# apollo510 register map
Vendor: Ambiq Micro; Series: Apollo; File version: 1.0
CPU: CM55 r1p1, little endian, MPU, FPU, double-precision FPU, DSP, I-cache, D-cache, VTOR, ITCM, DTCM, 4 interrupt priority bits, 0 interrupts, 8 SAU regions
Registers are 32-bit, read-write, reset 0x0 unless marked. A register's access mark holds for its fields unless they carry their own. Offsets are from the block's base; [hi:lo] are bit positions; {n}, {i} and the like mark numbered series; 'fields as' and 'values as' point back to an identical list.

## GPIO (part 5 of 7) — General Purpose IO
Base 0x40010000
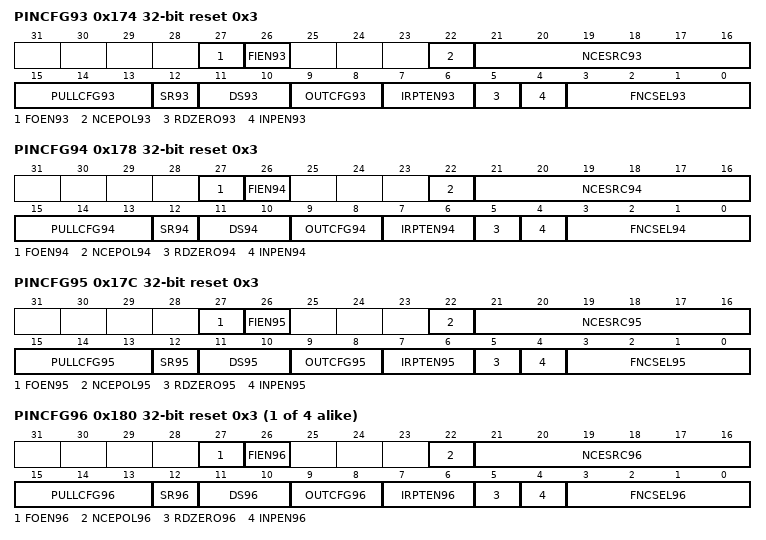
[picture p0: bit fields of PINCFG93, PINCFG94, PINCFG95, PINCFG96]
0x174 PINCFG93 reset 0x3 — Controls the operation of GPIO pin 93.
  [27] FOEN93 — Force output enable active regardless of function selected. Otherwise the selected function will enable the output only when needed
  [26] FIEN93 — Force input enable active regardless of function selected. Otherwise the selected function will enable the input only when needed
  [22] NCEPOL93 — Polarity select for NCE for GPIO 93
    0=LOW (Polarity is active low); 1=HIGH (Polarity is active high)
  [21:16] NCESRC93 — IOMSTR/MSPI N Chip Select 93, DISP control signals DE, CSX, and CS. Polarity is determined by CE_POLARITY field
    {v}=IOM0CE{v} (IOM 0 NCE {v} module) (v=0..3); {v}=IOM1CE{v-4} (IOM 1 NCE {v-4} module) (v=4..7); {v}=IOM2CE{v-8} (IOM 2 NCE {v-8} module) (v=8..11); {v}=IOM3CE{v-12} (IOM 3 NCE {v-12} module) (v=12..15); {v}=IOM4CE{v-16} (IOM 4 NCE {v-16} module) (v=16..19); {v}=IOM5CE{v-20} (IOM 5 NCE {v-20} module) (v=20..23); {v}=IOM6CE{v-24} (IOM 6 NCE {v-24} module) (v=24..27); {v}=IOM7CE{v-28} (IOM 7 NCE {v-28} module) (v=28..31); 48=DC_DPI_DE (DC DPI DE module); 49=DISP_CONT_CSX (DISP CONT CSX module); 50=DC_SPI_CS_N (DC SPI CS_N module); 51=DC_QSPI_CS_N (DC QSPI CS_N module); 52=DC_RESX (DC module RESX)
  [15:13] PULLCFG93 — Pullup/Pulldown configuration for GPIO 93
    0=DIS (No pullup or pulldown selected); 1=PD50K (50K Pulldown selected); 2=PU15K (1.5K Pullup selected); 3=PU6K (6K Pullup selected); 4=PU12K (12K Pullup selected); 5=PU24K (24K Pullup selected); 6=PU50K (50K Pullup selected); 7=PU100K (100K Pullup selected)
  [12] SR93 — Configure the slew rate
  [11:10] DS93 — Drive strength selection for GPIO 93
    0=0P1X (0.1x output driver selected); 1=0P5X (0.5x output driver selected)
  [9:8] OUTCFG93 — Pin IO mode selection for GPIO pin 93
    0=DIS (Output Disabled); 1=PUSHPULL (Output configured in push pull mode. Will drive 0 and 1 values on pin.); 2=OD (Output configured in open drain mode. Will only drive pin low, tristate otherwise.); 3=TS (Output configured in Tristate-able push pull mode. Will drive 0, 1 of HiZ on pin.)
  [7:6] IRPTEN93 — Interrupt enable for GPIO 93
    0=DIS (Interrupts are disabled for this GPIO); 1=INTFALL (Interrupts are enabled for falling edge transition on this GPIO); 2=INTRISE (Interrupts are enabled for rising edge transitions on this GPIO); 3=INTANY (Interrupts are enabled for any edge transition on this GPIO)
  [5] RDZERO93 — Return 0 for read data on GPIO 93
  [4] INPEN93 — Input enable for GPIO 93
  [3:0] FNCSEL93 — Function select for GPIO pin 93
    0=MNCE1_0 (MSPI Master 1 nCE 0 Signal); 3=GPIO (General purpose I/O); 6=CT93 (Timer/Counter input or output; Selection of direction is done via CTIMER register settings.); 7=NCE93 (IOMSTR N Chip Select. Polarity is determined by CE_POLARITY field); 8=OBSBUS13 (Observation bus bit 13); 9=VCMPO (Output of the voltage comparator signal); 11=FPIO (Fast PIO)
0x178 PINCFG94 reset 0x3 — Controls the operation of GPIO pin 94.
  [27] FOEN94 — Force output enable active regardless of function selected. Otherwise the selected function will enable the output only when needed
  [26] FIEN94 — Force input enable active regardless of function selected. Otherwise the selected function will enable the input only when needed
  [22] NCEPOL94 — Polarity select for NCE for GPIO 94
    values as PINCFG93.NCEPOL93
  [21:16] NCESRC94 — IOMSTR/MSPI N Chip Select 94, DISP control signals DE, CSX, and CS. Polarity is determined by CE_POLARITY field
    values as PINCFG93.NCESRC93
  [15:13] PULLCFG94 — Pullup/Pulldown configuration for GPIO 94
    values as PINCFG93.PULLCFG93
  [12] SR94 — Configure the slew rate
  [11:10] DS94 — Drive strength selection for GPIO 94
    values as PINCFG93.DS93
  [9:8] OUTCFG94 — Pin IO mode selection for GPIO pin 94
    values as PINCFG93.OUTCFG93
  [7:6] IRPTEN94 — Interrupt enable for GPIO 94
    values as PINCFG93.IRPTEN93
  [5] RDZERO94 — Return 0 for read data on GPIO 94
  [4] INPEN94 — Input enable for GPIO 94
  [3:0] FNCSEL94 — Function select for GPIO pin 94
    3=GPIO (General purpose I/O); 6=CT94 (Timer/Counter input or output; Selection of direction is done via CTIMER register settings.); 7=NCE94 (IOMSTR N Chip Select. Polarity is determined by CE_POLARITY field); 8=OBSBUS14 (Observation bus bit 14); 9=VCMPO (Output of the voltage comparator signal); 11=FPIO (Fast PIO)
0x17C PINCFG95 reset 0x3 — Controls the operation of GPIO pin 95.
  [27] FOEN95 — Force output enable active regardless of function selected. Otherwise the selected function will enable the output only when needed
  [26] FIEN95 — Force input enable active regardless of function selected. Otherwise the selected function will enable the input only when needed
  [22] NCEPOL95 — Polarity select for NCE for GPIO 95
    values as PINCFG93.NCEPOL93
  [21:16] NCESRC95 — IOMSTR/MSPI N Chip Select 95, DISP control signals DE, CSX, and CS. Polarity is determined by CE_POLARITY field
    values as PINCFG93.NCESRC93
  [15:13] PULLCFG95 — Pullup/Pulldown configuration for GPIO 95
    values as PINCFG93.PULLCFG93
  [12] SR95 — Configure the slew rate
  [11:10] DS95 — Drive strength selection for GPIO 95
    0=0P1X (0.1x output driver selected); 1=0P5X (0.5x output driver selected); 2=0P75X (0.75x output driver selected); 3=1P0X (1.0x output driver selected)
  [9:8] OUTCFG95 — Pin IO mode selection for GPIO pin 95
    values as PINCFG93.OUTCFG93
  [7:6] IRPTEN95 — Interrupt enable for GPIO 95
    values as PINCFG93.IRPTEN93
  [5] RDZERO95 — Return 0 for read data on GPIO 95
  [4] INPEN95 — Input enable for GPIO 95
  [3:0] FNCSEL95 — Function select for GPIO pin 95
    0=MSPI1_0 (MSPI Master 1 Interface Signal); 3=GPIO (General purpose I/O); 6=CT95 (Timer/Counter input or output; Selection of direction is done via CTIMER register settings.); 7=NCE95 (IOMSTR N Chip Select. Polarity is determined by CE_POLARITY field); 8=OBSBUS15 (Observation bus bit 15); 9=I2S0_SDIN (I2S Data input (I2S Master/Slave 0)); 11=FPIO (Fast PIO)
{0x0+4i} PINCFG{i} reset 0x3 (i=96..99) — Controls the operation of GPIO pin {i}.
  [27] FOEN{i} — Force output enable active regardless of function selected. Otherwise the selected function will enable the output only when needed
  [26] FIEN{i} — Force input enable active regardless of function selected. Otherwise the selected function will enable the input only when needed
  [22] NCEPOL{i} — Polarity select for NCE for GPIO {i}
    values as PINCFG93.NCEPOL93
  [21:16] NCESRC{i} — IOMSTR/MSPI N Chip Select {i}, DISP control signals DE, CSX, and CS. Polarity is determined by CE_POLARITY field
    values as PINCFG93.NCESRC93
  [15:13] PULLCFG{i} — Pullup/Pulldown configuration for GPIO {i}
    values as PINCFG93.PULLCFG93
  [12] SR{i} — Configure the slew rate
  [11:10] DS{i} — Drive strength selection for GPIO {i}
    values as PINCFG95.DS95
  [9:8] OUTCFG{i} — Pin IO mode selection for GPIO pin {i}
    values as PINCFG93.OUTCFG93
  [7:6] IRPTEN{i} — Interrupt enable for GPIO {i}
    values as PINCFG93.IRPTEN93
  [5] RDZERO{i} — Return 0 for read data on GPIO {i}
  [4] INPEN{i} — Input enable for GPIO {i}
  [3:0] FNCSEL{i} — Function select for GPIO pin {i}
    0=MSPI1_{i-95} (MSPI Master 1 Interface Signal); 3=GPIO (General purpose I/O); 6=CT{i} (Timer/Counter input or output; Selection of direction is done via CTIMER register settings.); 7=NCE{i} (IOMSTR N Chip Select. Polarity is determined by CE_POLARITY field); 8=OBSBUS{i-96} (Observation bus bit {i-96}); 11=FPIO (Fast PIO)
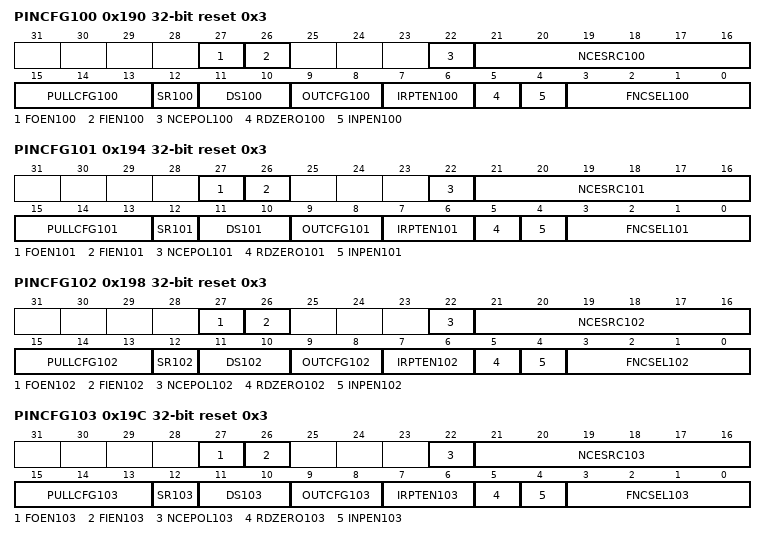
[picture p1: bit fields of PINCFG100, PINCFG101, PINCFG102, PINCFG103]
0x190 PINCFG100 reset 0x3 — Controls the operation of GPIO pin 100.
  [27] FOEN100 — Force output enable active regardless of function selected. Otherwise the selected function will enable the output only when needed
  [26] FIEN100 — Force input enable active regardless of function selected. Otherwise the selected function will enable the input only when needed
  [22] NCEPOL100 — Polarity select for NCE for GPIO 100
    values as PINCFG93.NCEPOL93
  [21:16] NCESRC100 — IOMSTR/MSPI N Chip Select 100, DISP control signals DE, CSX, and CS. Polarity is determined by CE_POLARITY field
    values as PINCFG93.NCESRC93
  [15:13] PULLCFG100 — Pullup/Pulldown configuration for GPIO 100
    values as PINCFG93.PULLCFG93
  [12] SR100 — Configure the slew rate
  [11:10] DS100 — Drive strength selection for GPIO 100
    values as PINCFG95.DS95
  [9:8] OUTCFG100 — Pin IO mode selection for GPIO pin 100
    values as PINCFG93.OUTCFG93
  [7:6] IRPTEN100 — Interrupt enable for GPIO 100
    values as PINCFG93.IRPTEN93
  [5] RDZERO100 — Return 0 for read data on GPIO 100
  [4] INPEN100 — Input enable for GPIO 100
  [3:0] FNCSEL100 — Function select for GPIO pin 100
    0=MSPI1_5 (MSPI Master 1 Interface Signal); 1=DISP_QSPI_D0_OUT (Display SPI Data0 Out); 2=DISP_QSPI_D0 (Display SPI Data0); 3=GPIO (General purpose I/O); 4=DISP_SPI_SD (Display SPI Data); 5=DISP_SPI_SDO (Display SPI Data Out); 6=CT100 (Timer/Counter input or output; Selection of direction is done via CTIMER register settings.); 7=NCE100 (IOMSTR N Chip Select. Polarity is determined by CE_POLARITY field); 8=OBSBUS4 (Observation bus bit 4); 9=I2S0_CLK (Bidirectional I2S Bit clock. Operates in output mode in master mode and input mode for slave mode. (I2S Master/Slave 0)); 11=FPIO (Fast PIO)
0x194 PINCFG101 reset 0x3 — Controls the operation of GPIO pin 101.
  [27] FOEN101 — Force output enable active regardless of function selected. Otherwise the selected function will enable the output only when needed
  [26] FIEN101 — Force input enable active regardless of function selected. Otherwise the selected function will enable the input only when needed
  [22] NCEPOL101 — Polarity select for NCE for GPIO 101
    values as PINCFG93.NCEPOL93
  [21:16] NCESRC101 — IOMSTR/MSPI N Chip Select 101, DISP control signals DE, CSX, and CS. Polarity is determined by CE_POLARITY field
    values as PINCFG93.NCESRC93
  [15:13] PULLCFG101 — Pullup/Pulldown configuration for GPIO 101
    values as PINCFG93.PULLCFG93
  [12] SR101 — Configure the slew rate
  [11:10] DS101 — Drive strength selection for GPIO 101
    values as PINCFG95.DS95
  [9:8] OUTCFG101 — Pin IO mode selection for GPIO pin 101
    values as PINCFG93.OUTCFG93
  [7:6] IRPTEN101 — Interrupt enable for GPIO 101
    values as PINCFG93.IRPTEN93
  [5] RDZERO101 — Return 0 for read data on GPIO 101
  [4] INPEN101 — Input enable for GPIO 101
  [3:0] FNCSEL101 — Function select for GPIO pin 101
    0=MSPI1_6 (MSPI Master 1 Interface Signal); 2=DISP_QSPI_D1 (Display SPI Data1); 3=GPIO (General purpose I/O); 4=DISP_SPI_DCX (Display SPI DCx); 6=CT101 (Timer/Counter input or output; Selection of direction is done via CTIMER register settings.); 7=NCE101 (IOMSTR N Chip Select. Polarity is determined by CE_POLARITY field); 8=OBSBUS5 (Observation bus bit 5); 9=I2S0_DATA (Bidirectional I2S Data. Operates in output mode in master mode and input mode for slave mode. (I2S Master/Slave 0)); 10=I2S0_SDOUT (I2S Data output (I2S Master/Slave 0)); 11=FPIO (Fast PIO)
0x198 PINCFG102 reset 0x3 — Controls the operation of GPIO pin 102.
  [27] FOEN102 — Force output enable active regardless of function selected. Otherwise the selected function will enable the output only when needed
  [26] FIEN102 — Force input enable active regardless of function selected. Otherwise the selected function will enable the input only when needed
  [22] NCEPOL102 — Polarity select for NCE for GPIO 102
    values as PINCFG93.NCEPOL93
  [21:16] NCESRC102 — IOMSTR/MSPI N Chip Select 102, DISP control signals DE, CSX, and CS. Polarity is determined by CE_POLARITY field
    values as PINCFG93.NCESRC93
  [15:13] PULLCFG102 — Pullup/Pulldown configuration for GPIO 102
    values as PINCFG93.PULLCFG93
  [12] SR102 — Configure the slew rate
  [11:10] DS102 — Drive strength selection for GPIO 102
    values as PINCFG95.DS95
  [9:8] OUTCFG102 — Pin IO mode selection for GPIO pin 102
    values as PINCFG93.OUTCFG93
  [7:6] IRPTEN102 — Interrupt enable for GPIO 102
    values as PINCFG93.IRPTEN93
  [5] RDZERO102 — Return 0 for read data on GPIO 102
  [4] INPEN102 — Input enable for GPIO 102
  [3:0] FNCSEL102 — Function select for GPIO pin 102
    0=MSPI1_7 (MSPI Master 1 Interface Signal); 2=DISP_QSPI_SCK (Display SPI CLK); 3=GPIO (General purpose I/O); 4=DISP_SPI_SCK (Display SPI Clock); 6=CT102 (Timer/Counter input or output; Selection of direction is done via CTIMER register settings.); 7=NCE102 (IOMSTR N Chip Select. Polarity is determined by CE_POLARITY field); 8=OBSBUS6 (Observation bus bit 6); 9=I2S0_WS (Bidirectional I2S L/R clock. Operates in output mode in master mode and input mode for slave mode. (I2S Master/Slave 0)); 11=FPIO (Fast PIO)
0x19C PINCFG103 reset 0x3 — Controls the operation of GPIO pin 103.
  [27] FOEN103 — Force output enable active regardless of function selected. Otherwise the selected function will enable the output only when needed
  [26] FIEN103 — Force input enable active regardless of function selected. Otherwise the selected function will enable the input only when needed
  [22] NCEPOL103 — Polarity select for NCE for GPIO 103
    values as PINCFG93.NCEPOL93
  [21:16] NCESRC103 — IOMSTR/MSPI N Chip Select 103, DISP control signals DE, CSX, and CS. Polarity is determined by CE_POLARITY field
    values as PINCFG93.NCESRC93
  [15:13] PULLCFG103 — Pullup/Pulldown configuration for GPIO 103
    values as PINCFG93.PULLCFG93
  [12] SR103 — Configure the slew rate
  [11:10] DS103 — Drive strength selection for GPIO 103
    values as PINCFG95.DS95
  [9:8] OUTCFG103 — Pin IO mode selection for GPIO pin 103
    values as PINCFG93.OUTCFG93
  [7:6] IRPTEN103 — Interrupt enable for GPIO 103
    values as PINCFG93.IRPTEN93
  [5] RDZERO103 — Return 0 for read data on GPIO 103
  [4] INPEN103 — Input enable for GPIO 103
  [3:0] FNCSEL103 — Function select for GPIO pin 103
    0=MSPI1_8 (MSPI Master 1 Interface Signal); 2=DISP_QSPI_D2 (Display SPI Data2); 3=GPIO (General purpose I/O); 4=DISP_SPI_SDI (Display SPI Data In); 6=CT103 (Timer/Counter input or output; Selection of direction is done via CTIMER register settings.); 7=NCE103 (IOMSTR N Chip Select. Polarity is determined by CE_POLARITY field); 8=OBSBUS7 (Observation bus bit 7); 11=FPIO (Fast PIO)
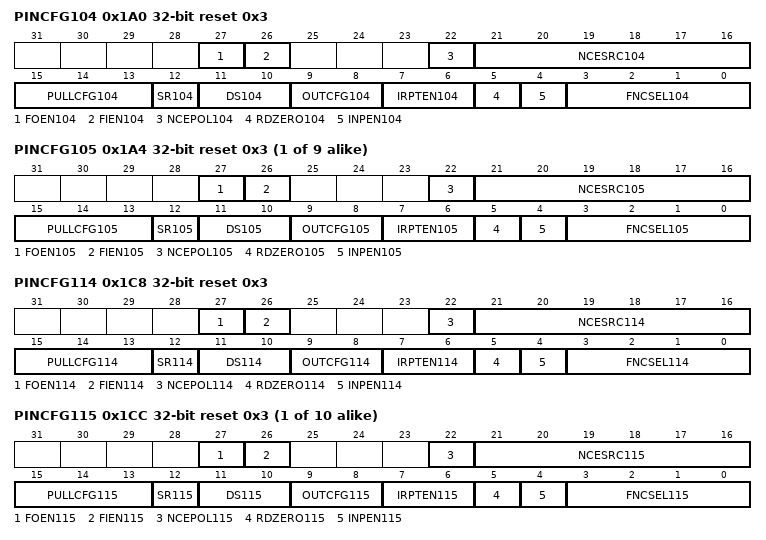
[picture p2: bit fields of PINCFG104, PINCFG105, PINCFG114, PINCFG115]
0x1A0 PINCFG104 reset 0x3 — Controls the operation of GPIO pin 104.
  [27] FOEN104 — Force output enable active regardless of function selected. Otherwise the selected function will enable the output only when needed
  [26] FIEN104 — Force input enable active regardless of function selected. Otherwise the selected function will enable the input only when needed
  [22] NCEPOL104 — Polarity select for NCE for GPIO 104
    values as PINCFG93.NCEPOL93
  [21:16] NCESRC104 — IOMSTR/MSPI N Chip Select 104, DISP control signals DE, CSX, and CS. Polarity is determined by CE_POLARITY field
    values as PINCFG93.NCESRC93
  [15:13] PULLCFG104 — Pullup/Pulldown configuration for GPIO 104
    values as PINCFG93.PULLCFG93
  [12] SR104 — Configure the slew rate
  [11:10] DS104 — Drive strength selection for GPIO 104
    values as PINCFG95.DS95
  [9:8] OUTCFG104 — Pin IO mode selection for GPIO pin 104
    values as PINCFG93.OUTCFG93
  [7:6] IRPTEN104 — Interrupt enable for GPIO 104
    values as PINCFG93.IRPTEN93
  [5] RDZERO104 — Return 0 for read data on GPIO 104
  [4] INPEN104 — Input enable for GPIO 104
  [3:0] FNCSEL104 — Function select for GPIO pin 104
    0=MSPI1_9 (MSPI Master 1 Interface Signal); 2=DISP_QSPI_D3 (Display SPI Data3); 3=GPIO (General purpose I/O); 4=DISP_SPI_RST (Display SPI RST); 6=CT104 (Timer/Counter input or output; Selection of direction is done via CTIMER register settings.); 7=NCE104 (IOMSTR N Chip Select. Polarity is determined by CE_POLARITY field); 8=OBSBUS8 (Observation bus bit 8); 11=FPIO (Fast PIO)
{0x0+4i} PINCFG{i} reset 0x3 (i=105..113) — Controls the operation of GPIO pin {i}.
  [27] FOEN{i} — Force output enable active regardless of function selected. Otherwise the selected function will enable the output only when needed
  [26] FIEN{i} — Force input enable active regardless of function selected. Otherwise the selected function will enable the input only when needed
  [22] NCEPOL{i} — Polarity select for NCE for GPIO {i}
    values as PINCFG93.NCEPOL93
  [21:16] NCESRC{i} — IOMSTR/MSPI N Chip Select {i}, DISP control signals DE, CSX, and CS. Polarity is determined by CE_POLARITY field
    values as PINCFG93.NCESRC93
  [15:13] PULLCFG{i} — Pullup/Pulldown configuration for GPIO {i}
    0=DIS (No pullup or pulldown selected); 1=PD50K (50K Pulldown selected); 2=PU50K (50K Pullup selected)
  [12] SR{i} — Configure high or low drive strength
    0=LDRV (Select the lower of the two drive strength selections); 1=HDRV (Select the higher of the two drive strength selections)
  [11:10] DS{i} — Drive strength selection for High Speed GPIO {i}
    0=0P12X_0P63X (0.12x output driver selected if SR{i} = 0, 0.63x output driver selected if SR{i} = 1); 1=0P25X_0P75X (0.25x output driver selected if SR{i} = 0, 0.75x output driver selected if SR{i} = 1); 2=0P37X_0P88X (0.37x output driver selected if SR{i} = 0, 0.88x output driver selected if SR{i} = 1); 3=0P5X_1P0X (0.5x output driver selected if SR{i} = 0, 1.0x output driver selected if SR{i} = 1)
  [9:8] OUTCFG{i} — Pin IO mode selection for GPIO pin {i}
    values as PINCFG93.OUTCFG93
  [7:6] IRPTEN{i} — Interrupt enable for GPIO {i}
    values as PINCFG93.IRPTEN93
  [5] RDZERO{i} — Return 0 for read data on GPIO {i}
  [4] INPEN{i} — Input enable for GPIO {i}
  [3:0] FNCSEL{i} — Function select for GPIO pin {i}
    0=MSPI3_{i-95} (MSPI Master 3 Interface Signal); 3=GPIO (General purpose I/O); 6=CT{i} (Timer/Counter input or output; Selection of direction is done via CTIMER register settings.); 7=NCE{i} (IOMSTR N Chip Select. Polarity is determined by CE_POLARITY field); 11=FPIO (Fast PIO)
0x1C8 PINCFG114 reset 0x3 — Controls the operation of GPIO pin 114.
  [27] FOEN114 — Force output enable active regardless of function selected. Otherwise the selected function will enable the output only when needed
  [26] FIEN114 — Force input enable active regardless of function selected. Otherwise the selected function will enable the input only when needed
  [22] NCEPOL114 — Polarity select for NCE for GPIO 114
    values as PINCFG93.NCEPOL93
  [21:16] NCESRC114 — IOMSTR/MSPI N Chip Select 114, DISP control signals DE, CSX, and CS. Polarity is determined by CE_POLARITY field
    values as PINCFG93.NCESRC93
  [15:13] PULLCFG114 — Pullup/Pulldown configuration for GPIO 114
    values as PINCFG93.PULLCFG93
  [12] SR114 — Configure the slew rate
  [11:10] DS114 — Drive strength selection for GPIO 114
    values as PINCFG95.DS95
  [9:8] OUTCFG114 — Pin IO mode selection for GPIO pin 114
    values as PINCFG93.OUTCFG93
  [7:6] IRPTEN114 — Interrupt enable for GPIO 114
    values as PINCFG93.IRPTEN93
  [5] RDZERO114 — Return 0 for read data on GPIO 114
  [4] INPEN114 — Input enable for GPIO 114
  [3:0] FNCSEL114 — Function select for GPIO pin 114
    1=MNCE3_0 (MSPI Master 3 nCE 0 Signal); 3=GPIO (General purpose I/O); 6=CT114 (Timer/Counter input or output; Selection of direction is done via CTIMER register settings.); 7=NCE114 (IOMSTR N Chip Select. Polarity is determined by CE_POLARITY field); 11=FPIO (Fast PIO)
{0x0+4i} PINCFG{i} reset 0x3 (i=115..124) — Controls the operation of GPIO pin {i}.
  [27] FOEN{i} — Force output enable active regardless of function selected. Otherwise the selected function will enable the output only when needed
  [26] FIEN{i} — Force input enable active regardless of function selected. Otherwise the selected function will enable the input only when needed
  [22] NCEPOL{i} — Polarity select for NCE for GPIO {i}
    values as PINCFG93.NCEPOL93
  [21:16] NCESRC{i} — IOMSTR/MSPI N Chip Select {i}, DISP control signals DE, CSX, and CS. Polarity is determined by CE_POLARITY field
    values as PINCFG93.NCESRC93
  [15:13] PULLCFG{i} — Pullup/Pulldown configuration for GPIO {i}
    values as PINCFG105.PULLCFG{i}
  [12] SR{i} — Configure high or low drive strength
    values as PINCFG105.SR{i}
  [11:10] DS{i} — Drive strength selection for High Speed GPIO {i}
    values as PINCFG105.DS{i}
  [9:8] OUTCFG{i} — Pin IO mode selection for GPIO pin {i}
    values as PINCFG93.OUTCFG93
  [7:6] IRPTEN{i} — Interrupt enable for GPIO {i}
    values as PINCFG93.IRPTEN93
  [5] RDZERO{i} — Return 0 for read data on GPIO {i}
  [4] INPEN{i} — Input enable for GPIO {i}
  [3:0] FNCSEL{i} — Function select for GPIO pin {i}
    0=MSPI3_{i-115} (MSPI Master 3 Interface Signal); 3=GPIO (General purpose I/O); 6=CT{i} (Timer/Counter input or output; Selection of direction is done via CTIMER register settings.); 7=NCE{i} (IOMSTR N Chip Select. Polarity is determined by CE_POLARITY field); 11=FPIO (Fast PIO)
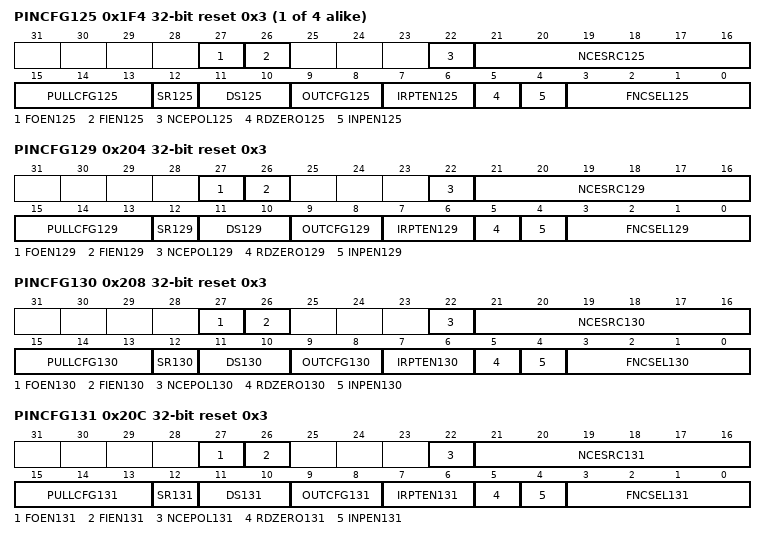
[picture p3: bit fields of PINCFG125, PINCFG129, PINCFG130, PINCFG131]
{0x0+4i} PINCFG{i} reset 0x3 (i=125..128) — Controls the operation of GPIO pin {i}.
  [27] FOEN{i} — Force output enable active regardless of function selected. Otherwise the selected function will enable the output only when needed
  [26] FIEN{i} — Force input enable active regardless of function selected. Otherwise the selected function will enable the input only when needed
  [22] NCEPOL{i} — Polarity select for NCE for GPIO {i}
    values as PINCFG93.NCEPOL93
  [21:16] NCESRC{i} — IOMSTR/MSPI N Chip Select {i}, DISP control signals DE, CSX, and CS. Polarity is determined by CE_POLARITY field
    values as PINCFG93.NCESRC93
  [15:13] PULLCFG{i} — Pullup/Pulldown configuration for GPIO {i}
    values as PINCFG93.PULLCFG93
  [12] SR{i} — Configure the slew rate
  [11:10] DS{i} — Drive strength selection for GPIO {i}
    values as PINCFG95.DS95
  [9:8] OUTCFG{i} — Pin IO mode selection for GPIO pin {i}
    values as PINCFG93.OUTCFG93
  [7:6] IRPTEN{i} — Interrupt enable for GPIO {i}
    values as PINCFG93.IRPTEN93
  [5] RDZERO{i} — Return 0 for read data on GPIO {i}
  [4] INPEN{i} — Input enable for GPIO {i}
  [3:0] FNCSEL{i} — Function select for GPIO pin {i}
    0=SDIF1_DAT{i-125} (SD/SDIO/MMC1 Data{i-125} pin); 3=GPIO (General purpose I/O); 6=CT{i} (Timer/Counter input or output; Selection of direction is done via CTIMER register settings.); 7=NCE{i} (IOMSTR N Chip Select. Polarity is determined by CE_POLARITY field); 11=FPIO (Fast PIO)
0x204 PINCFG129 reset 0x3 — Controls the operation of GPIO pin 129.
  [27] FOEN129 — Force output enable active regardless of function selected. Otherwise the selected function will enable the output only when needed
  [26] FIEN129 — Force input enable active regardless of function selected. Otherwise the selected function will enable the input only when needed
  [22] NCEPOL129 — Polarity select for NCE for GPIO 129
    values as PINCFG93.NCEPOL93
  [21:16] NCESRC129 — IOMSTR/MSPI N Chip Select 129, DISP control signals DE, CSX, and CS. Polarity is determined by CE_POLARITY field
    values as PINCFG93.NCESRC93
  [15:13] PULLCFG129 — Pullup/Pulldown configuration for GPIO 129
    values as PINCFG93.PULLCFG93
  [12] SR129 — Configure the slew rate
  [11:10] DS129 — Drive strength selection for GPIO 129
    values as PINCFG95.DS95
  [9:8] OUTCFG129 — Pin IO mode selection for GPIO pin 129
    values as PINCFG93.OUTCFG93
  [7:6] IRPTEN129 — Interrupt enable for GPIO 129
    values as PINCFG93.IRPTEN93
  [5] RDZERO129 — Return 0 for read data on GPIO 129
  [4] INPEN129 — Input enable for GPIO 129
  [3:0] FNCSEL129 — Function select for GPIO pin 129
    0=SDIF1_CLKOUT (SD/SDIO/MMC1 Clock to Card (CLK)); 3=GPIO (General purpose I/O); 6=CT129 (Timer/Counter input or output; Selection of direction is done via CTIMER register settings.); 7=NCE129 (IOMSTR N Chip Select. Polarity is determined by CE_POLARITY field); 11=FPIO (Fast PIO)
0x208 PINCFG130 reset 0x3 — Controls the operation of GPIO pin 130.
  [27] FOEN130 — Force output enable active regardless of function selected. Otherwise the selected function will enable the output only when needed
  [26] FIEN130 — Force input enable active regardless of function selected. Otherwise the selected function will enable the input only when needed
  [22] NCEPOL130 — Polarity select for NCE for GPIO 130
    values as PINCFG93.NCEPOL93
  [21:16] NCESRC130 — IOMSTR/MSPI N Chip Select 130, DISP control signals DE, CSX, and CS. Polarity is determined by CE_POLARITY field
    values as PINCFG93.NCESRC93
  [15:13] PULLCFG130 — Pullup/Pulldown configuration for GPIO 130
    values as PINCFG93.PULLCFG93
  [12] SR130 — Configure the slew rate
  [11:10] DS130 — Drive strength selection for GPIO 130
    values as PINCFG95.DS95
  [9:8] OUTCFG130 — Pin IO mode selection for GPIO pin 130
    values as PINCFG93.OUTCFG93
  [7:6] IRPTEN130 — Interrupt enable for GPIO 130
    values as PINCFG93.IRPTEN93
  [5] RDZERO130 — Return 0 for read data on GPIO 130
  [4] INPEN130 — Input enable for GPIO 130
  [3:0] FNCSEL130 — Function select for GPIO pin 130
    0=SDIF1_DAT4 (SD/SDIO/MMC1 Data4 pin); 1=MNCE0_0 (MSPI Master 0 nCE 0 Signal); 3=GPIO (General purpose I/O); 6=CT130 (Timer/Counter input or output; Selection of direction is done via CTIMER register settings.); 7=NCE130 (IOMSTR N Chip Select. Polarity is determined by CE_POLARITY field); 10=I2S1_CLK (Bidirectional I2S Bit clock. Operates in output mode in master mode and input mode for slave mode. (I2S Master/Slave 1)); 11=FPIO (Fast PIO)
0x20C PINCFG131 reset 0x3 — Controls the operation of GPIO pin 131.
  [27] FOEN131 — Force output enable active regardless of function selected. Otherwise the selected function will enable the output only when needed
  [26] FIEN131 — Force input enable active regardless of function selected. Otherwise the selected function will enable the input only when needed
  [22] NCEPOL131 — Polarity select for NCE for GPIO 131
    values as PINCFG93.NCEPOL93
  [21:16] NCESRC131 — IOMSTR/MSPI N Chip Select 131, DISP control signals DE, CSX, and CS. Polarity is determined by CE_POLARITY field
    values as PINCFG93.NCESRC93
  [15:13] PULLCFG131 — Pullup/Pulldown configuration for GPIO 131
    values as PINCFG93.PULLCFG93
  [12] SR131 — Configure the slew rate
  [11:10] DS131 — Drive strength selection for GPIO 131
    values as PINCFG95.DS95
  [9:8] OUTCFG131 — Pin IO mode selection for GPIO pin 131
    values as PINCFG93.OUTCFG93
  [7:6] IRPTEN131 — Interrupt enable for GPIO 131
    values as PINCFG93.IRPTEN93
  [5] RDZERO131 — Return 0 for read data on GPIO 131
  [4] INPEN131 — Input enable for GPIO 131
  [3:0] FNCSEL131 — Function select for GPIO pin 131
    0=SDIF1_DAT5 (SD/SDIO/MMC1 Data5 pin); 1=MNCE3_0 (MSPI Master 3 nCE 0 Signal); 3=GPIO (General purpose I/O); 6=CT131 (Timer/Counter input or output; Selection of direction is done via CTIMER register settings.); 7=NCE131 (IOMSTR N Chip Select. Polarity is determined by CE_POLARITY field); 9=I2S1_DATA (Bidirectional I2S Data. Operates in output mode in master mode and input mode for slave mode. (I2S Master/Slave 1)); 10=I2S1_SDOUT (I2S Data output (I2S Master/Slave 1)); 11=FPIO (Fast PIO)
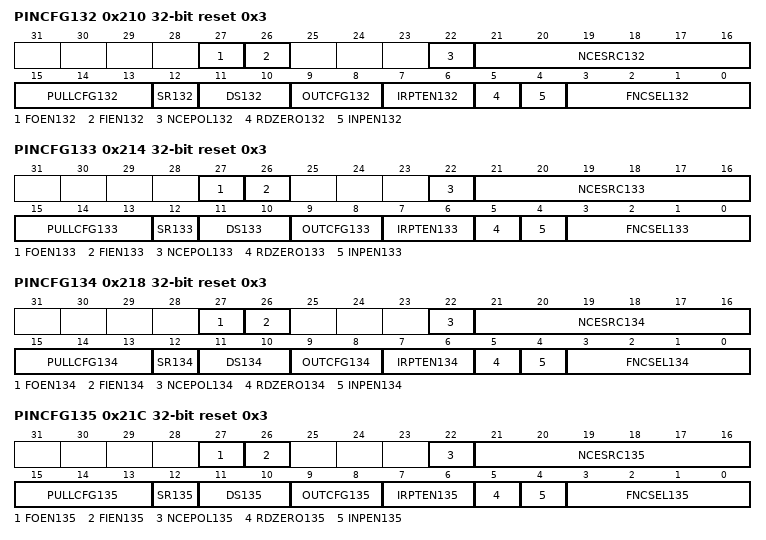
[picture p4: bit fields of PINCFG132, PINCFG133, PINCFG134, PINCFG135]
0x210 PINCFG132 reset 0x3 — Controls the operation of GPIO pin 132.
  [27] FOEN132 — Force output enable active regardless of function selected. Otherwise the selected function will enable the output only when needed
  [26] FIEN132 — Force input enable active regardless of function selected. Otherwise the selected function will enable the input only when needed
  [22] NCEPOL132 — Polarity select for NCE for GPIO 132
    values as PINCFG93.NCEPOL93
  [21:16] NCESRC132 — IOMSTR/MSPI N Chip Select 132, DISP control signals DE, CSX, and CS. Polarity is determined by CE_POLARITY field
    values as PINCFG93.NCESRC93
  [15:13] PULLCFG132 — Pullup/Pulldown configuration for GPIO 132
    values as PINCFG93.PULLCFG93
  [12] SR132 — Configure the slew rate
  [11:10] DS132 — Drive strength selection for GPIO 132
    values as PINCFG95.DS95
  [9:8] OUTCFG132 — Pin IO mode selection for GPIO pin 132
    values as PINCFG93.OUTCFG93
  [7:6] IRPTEN132 — Interrupt enable for GPIO 132
    values as PINCFG93.IRPTEN93
  [5] RDZERO132 — Return 0 for read data on GPIO 132
  [4] INPEN132 — Input enable for GPIO 132
  [3:0] FNCSEL132 — Function select for GPIO pin 132
    0=SDIF1_DAT6 (SD/SDIO/MMC1 Data6 pin); 3=GPIO (General purpose I/O); 6=CT132 (Timer/Counter input or output; Selection of direction is done via CTIMER register settings.); 7=NCE132 (IOMSTR N Chip Select. Polarity is determined by CE_POLARITY field); 10=I2S1_WS (Bidirectional I2S L/R clock. Operates in output mode in master mode and input mode for slave mode. (I2S Master/Slave 1)); 11=FPIO (Fast PIO)
0x214 PINCFG133 reset 0x3 — Controls the operation of GPIO pin 133.
  [27] FOEN133 — Force output enable active regardless of function selected. Otherwise the selected function will enable the output only when needed
  [26] FIEN133 — Force input enable active regardless of function selected. Otherwise the selected function will enable the input only when needed
  [22] NCEPOL133 — Polarity select for NCE for GPIO 133
    values as PINCFG93.NCEPOL93
  [21:16] NCESRC133 — IOMSTR/MSPI N Chip Select 133, DISP control signals DE, CSX, and CS. Polarity is determined by CE_POLARITY field
    values as PINCFG93.NCESRC93
  [15:13] PULLCFG133 — Pullup/Pulldown configuration for GPIO 133
    values as PINCFG93.PULLCFG93
  [12] SR133 — Configure the slew rate
  [11:10] DS133 — Drive strength selection for GPIO 133
    values as PINCFG95.DS95
  [9:8] OUTCFG133 — Pin IO mode selection for GPIO pin 133
    values as PINCFG93.OUTCFG93
  [7:6] IRPTEN133 — Interrupt enable for GPIO 133
    values as PINCFG93.IRPTEN93
  [5] RDZERO133 — Return 0 for read data on GPIO 133
  [4] INPEN133 — Input enable for GPIO 133
  [3:0] FNCSEL133 — Function select for GPIO pin 133
    0=SDIF1_DAT7 (SD/SDIO/MMC1 Data7 pin); 3=GPIO (General purpose I/O); 6=CT133 (Timer/Counter input or output; Selection of direction is done via CTIMER register settings.); 7=NCE133 (IOMSTR N Chip Select. Polarity is determined by CE_POLARITY field); 10=I2S1_SDIN (I2S Data input (I2S Master/Slave 1)); 11=FPIO (Fast PIO)
0x218 PINCFG134 reset 0x3 — Controls the operation of GPIO pin 134.
  [27] FOEN134 — Force output enable active regardless of function selected. Otherwise the selected function will enable the output only when needed
  [26] FIEN134 — Force input enable active regardless of function selected. Otherwise the selected function will enable the input only when needed
  [22] NCEPOL134 — Polarity select for NCE for GPIO 134
    values as PINCFG93.NCEPOL93
  [21:16] NCESRC134 — IOMSTR/MSPI N Chip Select 134, DISP control signals DE, CSX, and CS. Polarity is determined by CE_POLARITY field
    values as PINCFG93.NCESRC93
  [15:13] PULLCFG134 — Pullup/Pulldown configuration for GPIO 134
    values as PINCFG93.PULLCFG93
  [12] SR134 — Configure the slew rate
  [11:10] DS134 — Drive strength selection for GPIO 134
    values as PINCFG95.DS95
  [9:8] OUTCFG134 — Pin IO mode selection for GPIO pin 134
    values as PINCFG93.OUTCFG93
  [7:6] IRPTEN134 — Interrupt enable for GPIO 134
    values as PINCFG93.IRPTEN93
  [5] RDZERO134 — Return 0 for read data on GPIO 134
  [4] INPEN134 — Input enable for GPIO 134
  [3:0] FNCSEL134 — Function select for GPIO pin 134
    0=SDIF1_CMD (SD/SDIO/MMC1 CMD pin); 3=GPIO (General purpose I/O); 6=CT134 (Timer/Counter input or output; Selection of direction is done via CTIMER register settings.); 7=NCE134 (IOMSTR N Chip Select. Polarity is determined by CE_POLARITY field); 11=FPIO (Fast PIO)
0x21C PINCFG135 reset 0x3 — Controls the operation of GPIO pin 135.
  [27] FOEN135 — Force output enable active regardless of function selected. Otherwise the selected function will enable the output only when needed
  [26] FIEN135 — Force input enable active regardless of function selected. Otherwise the selected function will enable the input only when needed
  [22] NCEPOL135 — Polarity select for NCE for GPIO 135
    values as PINCFG93.NCEPOL93
  [21:16] NCESRC135 — IOMSTR/MSPI N Chip Select 135, DISP control signals DE, CSX, and CS. Polarity is determined by CE_POLARITY field
    values as PINCFG93.NCESRC93
  [15:13] PULLCFG135 — Pullup/Pulldown configuration for GPIO 135
    values as PINCFG93.PULLCFG93
  [12] SR135 — Configure the slew rate
  [11:10] DS135 — Drive strength selection for GPIO 135
    values as PINCFG93.DS93
  [9:8] OUTCFG135 — Pin IO mode selection for GPIO pin 135
    values as PINCFG93.OUTCFG93
  [7:6] IRPTEN135 — Interrupt enable for GPIO 135
    values as PINCFG93.IRPTEN93
  [5] RDZERO135 — Return 0 for read data on GPIO 135
  [4] INPEN135 — Input enable for GPIO 135
  [3:0] FNCSEL135 — Function select for GPIO pin 135
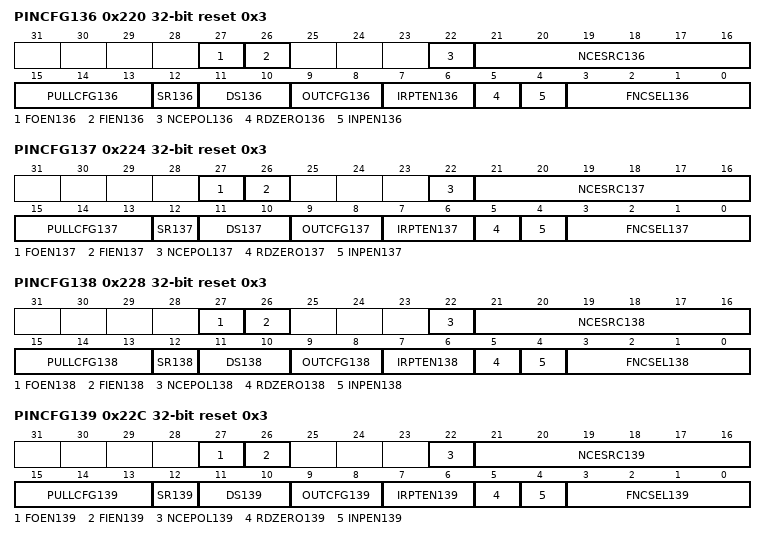
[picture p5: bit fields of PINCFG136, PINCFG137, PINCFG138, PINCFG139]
0x220 PINCFG136 reset 0x3 — Controls the operation of GPIO pin 136.
  [27] FOEN136 — Force output enable active regardless of function selected. Otherwise the selected function will enable the output only when needed
  [26] FIEN136 — Force input enable active regardless of function selected. Otherwise the selected function will enable the input only when needed
  [22] NCEPOL136 — Polarity select for NCE for GPIO 136
    values as PINCFG93.NCEPOL93
  [21:16] NCESRC136 — IOMSTR/MSPI N Chip Select 136, DISP control signals DE, CSX, and CS. Polarity is determined by CE_POLARITY field
    values as PINCFG93.NCESRC93
  [15:13] PULLCFG136 — Pullup/Pulldown configuration for GPIO 136
    values as PINCFG93.PULLCFG93
  [12] SR136 — Configure the slew rate
  [11:10] DS136 — Drive strength selection for GPIO 136
    values as PINCFG93.DS93
  [9:8] OUTCFG136 — Pin IO mode selection for GPIO pin 136
    values as PINCFG93.OUTCFG93
  [7:6] IRPTEN136 — Interrupt enable for GPIO 136
    values as PINCFG93.IRPTEN93
  [5] RDZERO136 — Return 0 for read data on GPIO 136
  [4] INPEN136 — Input enable for GPIO 136
  [3:0] FNCSEL136 — Function select for GPIO pin 136
    1=DISP_D15 (Display Data 15); 3=GPIO (General purpose I/O); 6=CT136 (Timer/Counter input or output; Selection of direction is done via CTIMER register settings.); 7=NCE136 (IOMSTR N Chip Select. Polarity is determined by CE_POLARITY field); 11=FPIO (Fast PIO)
0x224 PINCFG137 reset 0x3 — Controls the operation of GPIO pin 137.
  [27] FOEN137 — Force output enable active regardless of function selected. Otherwise the selected function will enable the output only when needed
  [26] FIEN137 — Force input enable active regardless of function selected. Otherwise the selected function will enable the input only when needed
  [22] NCEPOL137 — Polarity select for NCE for GPIO 137
    values as PINCFG93.NCEPOL93
  [21:16] NCESRC137 — IOMSTR/MSPI N Chip Select 137, DISP control signals DE, CSX, and CS. Polarity is determined by CE_POLARITY field
    values as PINCFG93.NCESRC93
  [15:13] PULLCFG137 — Pullup/Pulldown configuration for GPIO 137
    values as PINCFG93.PULLCFG93
  [12] SR137 — Configure the slew rate
  [11:10] DS137 — Drive strength selection for GPIO 137
    values as PINCFG93.DS93
  [9:8] OUTCFG137 — Pin IO mode selection for GPIO pin 137
    values as PINCFG93.OUTCFG93
  [7:6] IRPTEN137 — Interrupt enable for GPIO 137
    values as PINCFG93.IRPTEN93
  [5] RDZERO137 — Return 0 for read data on GPIO 137
  [4] INPEN137 — Input enable for GPIO 137
  [3:0] FNCSEL137 — Function select for GPIO pin 137
0x228 PINCFG138 reset 0x3 — Controls the operation of GPIO pin 138.
  [27] FOEN138 — Force output enable active regardless of function selected. Otherwise the selected function will enable the output only when needed
  [26] FIEN138 — Force input enable active regardless of function selected. Otherwise the selected function will enable the input only when needed
  [22] NCEPOL138 — Polarity select for NCE for GPIO 138
    values as PINCFG93.NCEPOL93
  [21:16] NCESRC138 — IOMSTR/MSPI N Chip Select 138, DISP control signals DE, CSX, and CS. Polarity is determined by CE_POLARITY field
    values as PINCFG93.NCESRC93
  [15:13] PULLCFG138 — Pullup/Pulldown configuration for GPIO 138
    values as PINCFG93.PULLCFG93
  [12] SR138 — Configure the slew rate
  [11:10] DS138 — Drive strength selection for GPIO 138
    values as PINCFG93.DS93
  [9:8] OUTCFG138 — Pin IO mode selection for GPIO pin 138
    values as PINCFG93.OUTCFG93
  [7:6] IRPTEN138 — Interrupt enable for GPIO 138
    values as PINCFG93.IRPTEN93
  [5] RDZERO138 — Return 0 for read data on GPIO 138
  [4] INPEN138 — Input enable for GPIO 138
  [3:0] FNCSEL138 — Function select for GPIO pin 138
    0=MNCE1_1 (MSPI Master 1 nCE 1 Signal); 1=32KHzXT (32kHZ from analog); 3=GPIO (General purpose I/O); 6=CT138 (Timer/Counter input or output; Selection of direction is done via CTIMER register settings.); 7=NCE138 (IOMSTR N Chip Select. Polarity is determined by CE_POLARITY field); 9=I2S0_SDIN (I2S Data input (I2S Master/Slave 0)); 11=FPIO (Fast PIO)
0x22C PINCFG139 reset 0x3 — Controls the operation of GPIO pin 139.
  [27] FOEN139 — Force output enable active regardless of function selected. Otherwise the selected function will enable the output only when needed
  [26] FIEN139 — Force input enable active regardless of function selected. Otherwise the selected function will enable the input only when needed
  [22] NCEPOL139 — Polarity select for NCE for GPIO 139
    values as PINCFG93.NCEPOL93
  [21:16] NCESRC139 — IOMSTR/MSPI N Chip Select 139, DISP control signals DE, CSX, and CS. Polarity is determined by CE_POLARITY field
    values as PINCFG93.NCESRC93
  [15:13] PULLCFG139 — Pullup/Pulldown configuration for GPIO 139
    values as PINCFG93.PULLCFG93
  [12] SR139 — Configure the slew rate
  [11:10] DS139 — Drive strength selection for GPIO 139
    values as PINCFG93.DS93
  [9:8] OUTCFG139 — Pin IO mode selection for GPIO pin 139
    values as PINCFG93.OUTCFG93
  [7:6] IRPTEN139 — Interrupt enable for GPIO 139
    values as PINCFG93.IRPTEN93
  [5] RDZERO139 — Return 0 for read data on GPIO 139
  [4] INPEN139 — Input enable for GPIO 139
  [3:0] FNCSEL139 — Function select for GPIO pin 139
    3=GPIO (General purpose I/O); 6=CT139 (Timer/Counter input or output; Selection of direction is done via CTIMER register settings.); 7=NCE139 (IOMSTR N Chip Select. Polarity is determined by CE_POLARITY field); 10=I2S0_SDIN (I2S Data input (I2S Master/Slave 0)); 11=FPIO (Fast PIO)
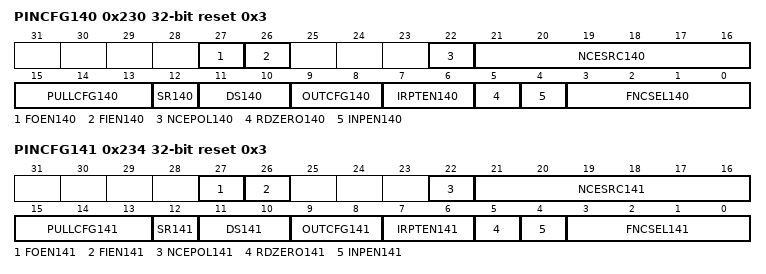
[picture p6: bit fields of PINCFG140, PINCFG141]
0x230 PINCFG140 reset 0x3 — Controls the operation of GPIO pin 140.
  [27] FOEN140 — Force output enable active regardless of function selected. Otherwise the selected function will enable the output only when needed
  [26] FIEN140 — Force input enable active regardless of function selected. Otherwise the selected function will enable the input only when needed
  [22] NCEPOL140 — Polarity select for NCE for GPIO 140
    values as PINCFG93.NCEPOL93
  [21:16] NCESRC140 — IOMSTR/MSPI N Chip Select 140, DISP control signals DE, CSX, and CS. Polarity is determined by CE_POLARITY field
    values as PINCFG93.NCESRC93
  [15:13] PULLCFG140 — Pullup/Pulldown configuration for GPIO 140
    values as PINCFG93.PULLCFG93
  [12] SR140 — Configure the slew rate
  [11:10] DS140 — Drive strength selection for GPIO 140
    values as PINCFG93.DS93
  [9:8] OUTCFG140 — Pin IO mode selection for GPIO pin 140
    values as PINCFG93.OUTCFG93
  [7:6] IRPTEN140 — Interrupt enable for GPIO 140
    values as PINCFG93.IRPTEN93
  [5] RDZERO140 — Return 0 for read data on GPIO 140
  [4] INPEN140 — Input enable for GPIO 140
  [3:0] FNCSEL140 — Function select for GPIO pin 140
    1=DISP_D16 (Display Data 16); 3=GPIO (General purpose I/O); 6=CT140 (Timer/Counter input or output; Selection of direction is done via CTIMER register settings.); 7=NCE140 (IOMSTR N Chip Select. Polarity is determined by CE_POLARITY field); 11=FPIO (Fast PIO)
0x234 PINCFG141 reset 0x3 — Controls the operation of GPIO pin 141.
  [27] FOEN141 — Force output enable active regardless of function selected. Otherwise the selected function will enable the output only when needed
  [26] FIEN141 — Force input enable active regardless of function selected. Otherwise the selected function will enable the input only when needed
  [22] NCEPOL141 — Polarity select for NCE for GPIO 141
    values as PINCFG93.NCEPOL93
  [21:16] NCESRC141 — IOMSTR/MSPI N Chip Select 141, DISP control signals DE, CSX, and CS. Polarity is determined by CE_POLARITY field
    values as PINCFG93.NCESRC93
  [15:13] PULLCFG141 — Pullup/Pulldown configuration for GPIO 141
    values as PINCFG93.PULLCFG93
  [12] SR141 — Configure the slew rate
  [11:10] DS141 — Drive strength selection for GPIO 141
    values as PINCFG93.DS93
  [9:8] OUTCFG141 — Pin IO mode selection for GPIO pin 141
    values as PINCFG93.OUTCFG93
  [7:6] IRPTEN141 — Interrupt enable for GPIO 141
    values as PINCFG93.IRPTEN93
  [5] RDZERO141 — Return 0 for read data on GPIO 141
  [4] INPEN141 — Input enable for GPIO 141
  [3:0] FNCSEL141 — Function select for GPIO pin 141
    1=DISP_D17 (Display Data 17); 3=GPIO (General purpose I/O); 6=CT141 (Timer/Counter input or output; Selection of direction is done via CTIMER register settings.); 7=NCE141 (IOMSTR N Chip Select. Polarity is determined by CE_POLARITY field); 11=FPIO (Fast PIO)
